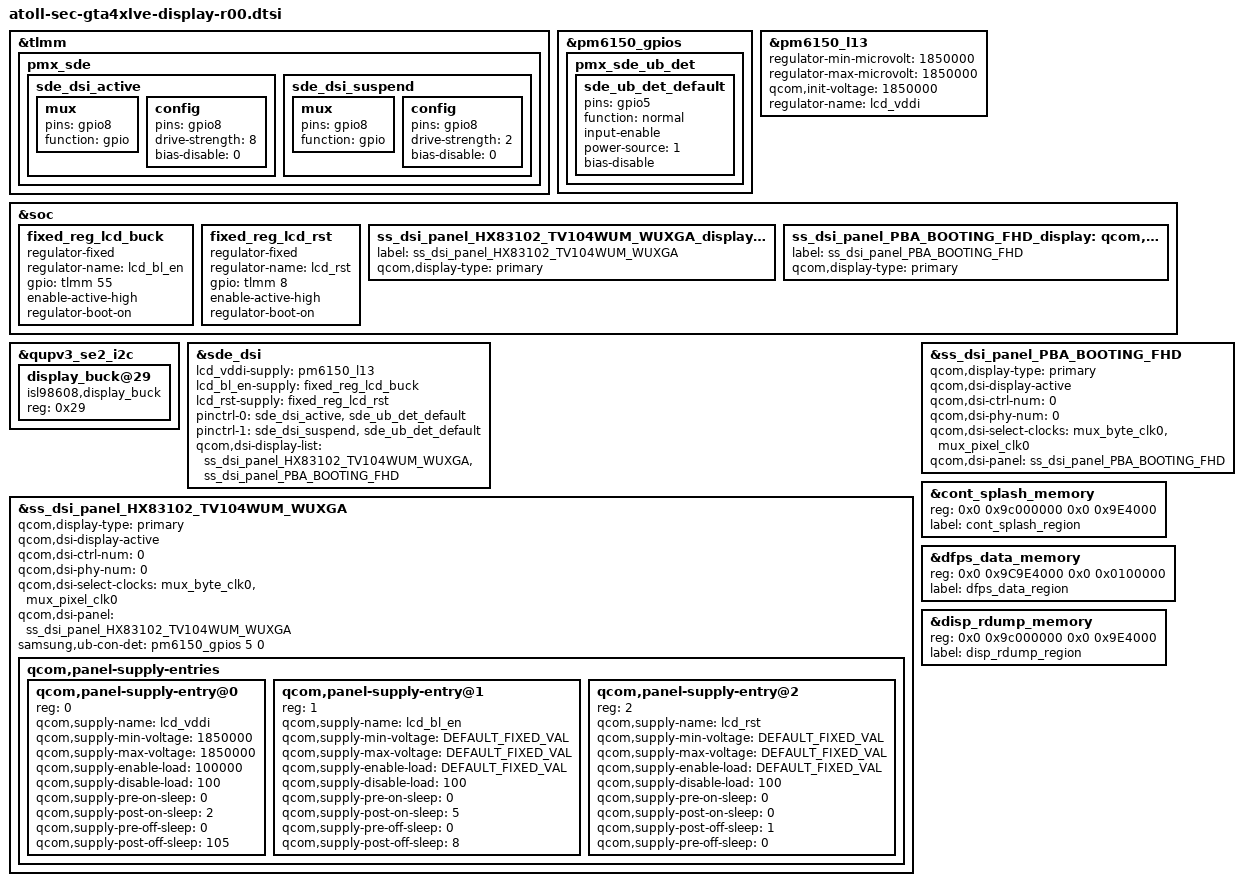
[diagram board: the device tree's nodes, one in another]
/* Copyright (c) 2016-2019, The Linux Foundation. All rights reserved.
 *
 * This program is free software; you can redistribute it and/or modify
 * it under the terms of the GNU General Public License version 2 and
 * only version 2 as published by the Free Software Foundation.
 *
 * This program is distributed in the hope that it will be useful,
 * but WITHOUT ANY WARRANTY; without even the implied warranty of
 * MERCHANTABILITY or FITNESS FOR A PARTICULAR PURPOSE.  See the
 * GNU General Public License for more details.
 */

#include "../../../../../../drivers/gpu/drm/msm/samsung_lego/HX83102_TV104WUM/dsi_panel_HX83102_TV104WUM_wuxga_video.dtsi"
#include "../../../../../../drivers/gpu/drm/msm/samsung_lego/PBA_BOOTING/dsi_panel_PBA_BOOTING_fhd_video.dtsi"

#define DEFAULT_FIXED_VAL	0

&tlmm {
	pmx_sde: pmx_sde {
		sde_dsi_active: sde_dsi_active {
			mux {
				pins = "gpio8";
				function = "gpio";
			};

			config {
				pins = "gpio8";
				drive-strength = <8>;   /* 8 mA */
				bias-disable = <0>;   /* no pull */
			};
		};
		sde_dsi_suspend: sde_dsi_suspend {
			mux {
				pins = "gpio8";
				function = "gpio";
			};

			config {
				pins = "gpio8";
				drive-strength = <2>;   /* 2 mA */
				bias-disable = <0>;   /* no pull */
			};
		};
	};
};

&pm6150_gpios {
	pmx_sde_ub_det {
		sde_ub_det_default: sde_ub_det_default {
			pins = "gpio5";
			function = "normal";
			input-enable;
			power-source = <1>;
			bias-disable; /* No PULL */
		};
	};
};

&pm6150_l13 {
	regulator-min-microvolt = <1850000>;
	regulator-max-microvolt = <1850000>;
	qcom,init-voltage = <1850000>;
	regulator-name = "lcd_vddi";
};

&soc {
	fixed_reg_lcd_buck: fixed_reg_lcd_buck {
		compatible = "regulator-fixed";
		status = "okay";
		regulator-name = "lcd_bl_en";
		gpio = <&tlmm 55 0>;
		enable-active-high;
		regulator-boot-on;
	};
};

&soc {
	fixed_reg_lcd_rst: fixed_reg_lcd_rst {
		compatible = "regulator-fixed";
		status = "okay";
		regulator-name = "lcd_rst";
		gpio = <&tlmm 8 0>;
		enable-active-high;
		regulator-boot-on;
	};
};

&qupv3_se2_i2c {
	status = "ok";

	display_buck@29{
		compatible = "isl98608,display_buck";
		reg = <0x29>;
	};
};

&soc {
	/* Tab S6 Lite panel */
	ss_dsi_panel_HX83102_TV104WUM_WUXGA_display: qcom,dsi-display@9 {
		label = "ss_dsi_panel_HX83102_TV104WUM_WUXGA";
		qcom,display-type = "primary";

	};

	/* PBA */
	ss_dsi_panel_PBA_BOOTING_FHD_display: qcom,dsi-display@10 {
		label = "ss_dsi_panel_PBA_BOOTING_FHD";
		qcom,display-type = "primary";

	};
};

&sde_dsi {
	lcd_vddi-supply = <&pm6150_l13>; /* 1.8V, VREG_L13A_1P8 */
	lcd_bl_en-supply = <&fixed_reg_lcd_buck>;
	lcd_rst-supply = <&fixed_reg_lcd_rst>;

	pinctrl-names = "panel_active", "panel_suspend";
	pinctrl-0 = <&sde_dsi_active &sde_ub_det_default>;
	pinctrl-1 = <&sde_dsi_suspend &sde_ub_det_default>;
	qcom,dsi-display-list =
		<&ss_dsi_panel_HX83102_TV104WUM_WUXGA
		&ss_dsi_panel_PBA_BOOTING_FHD>;
};

&ss_dsi_panel_HX83102_TV104WUM_WUXGA {
	qcom,display-type = "primary";
	qcom,dsi-display-active;

	qcom,dsi-ctrl-num = <0>;
	qcom,dsi-phy-num = <0>;
	qcom,dsi-select-clocks = "mux_byte_clk0", "mux_pixel_clk0";

	qcom,dsi-panel = <&ss_dsi_panel_HX83102_TV104WUM_WUXGA>;

	/*qcom,platform-reset-gpio = <&tlmm 8 0>;*/

	samsung,ub-con-det = <&pm6150_gpios 5 0>; /* LCD_CON_DET*/

	qcom,panel-supply-entries {
		#address-cells = <1>;
		#size-cells = <0>;

		qcom,panel-supply-entry@0 {
		    reg = <0>;
		    qcom,supply-name = "lcd_vddi";
		    qcom,supply-min-voltage = <1850000>;
		    qcom,supply-max-voltage = <1850000>;
		    qcom,supply-enable-load = <100000>;
		    qcom,supply-disable-load = <100>;
		    qcom,supply-pre-on-sleep = <0>; /* unit is ms*/
		    qcom,supply-post-on-sleep = <2>;
		    qcom,supply-pre-off-sleep = <0>;
		    qcom,supply-post-off-sleep = <105>;
		};

		qcom,panel-supply-entry@1 {
		    reg = <1>;
		    qcom,supply-name = "lcd_bl_en";
		    qcom,supply-min-voltage = <DEFAULT_FIXED_VAL>;
		    qcom,supply-max-voltage = <DEFAULT_FIXED_VAL>;
		    qcom,supply-enable-load = <DEFAULT_FIXED_VAL>;
		    qcom,supply-disable-load = <100>;
		    qcom,supply-pre-on-sleep = <0>; /* unit is ms*/
		    qcom,supply-post-on-sleep = <5>;
		    qcom,supply-pre-off-sleep = <0>;
		    qcom,supply-post-off-sleep = <8>;
		};

		qcom,panel-supply-entry@2 {
			reg = <2>;
			qcom,supply-name = "lcd_rst";
			qcom,supply-min-voltage = <DEFAULT_FIXED_VAL>;
			qcom,supply-max-voltage = <DEFAULT_FIXED_VAL>;
			qcom,supply-enable-load = <DEFAULT_FIXED_VAL>;
			qcom,supply-disable-load = <100>;
			qcom,supply-pre-on-sleep = <0>; /* unit is ms*/
			qcom,supply-post-on-sleep = <0>;
			qcom,supply-post-off-sleep = <1>;
			qcom,supply-pre-off-sleep = <0>;
		};
	};
};

&ss_dsi_panel_PBA_BOOTING_FHD {
	qcom,display-type = "primary";
	qcom,dsi-display-active;

	qcom,dsi-ctrl-num = <0>;
	qcom,dsi-phy-num = <0>;
	qcom,dsi-select-clocks = "mux_byte_clk0", "mux_pixel_clk0";

	qcom,dsi-panel = <&ss_dsi_panel_PBA_BOOTING_FHD>;
};

&cont_splash_memory {
	reg = <0x0 0x9c000000 0x0 0x9E4000>; //0x9E4000 is roundup(1080 * 2400 * 4, 4K)
	label = "cont_splash_region";
};

&dfps_data_memory {
	reg = <0x0 0x9C9E4000 0x0 0x0100000>; //0x9C9E4000 is 0x9c000000 + 0x9E4000
	label = "dfps_data_region";
};

&disp_rdump_memory {
	reg = <0x0 0x9c000000 0x0 0x9E4000>; //0x9E4000 is roundup(1080 * 2400 * 4, 4K)
	label = "disp_rdump_region";
};
